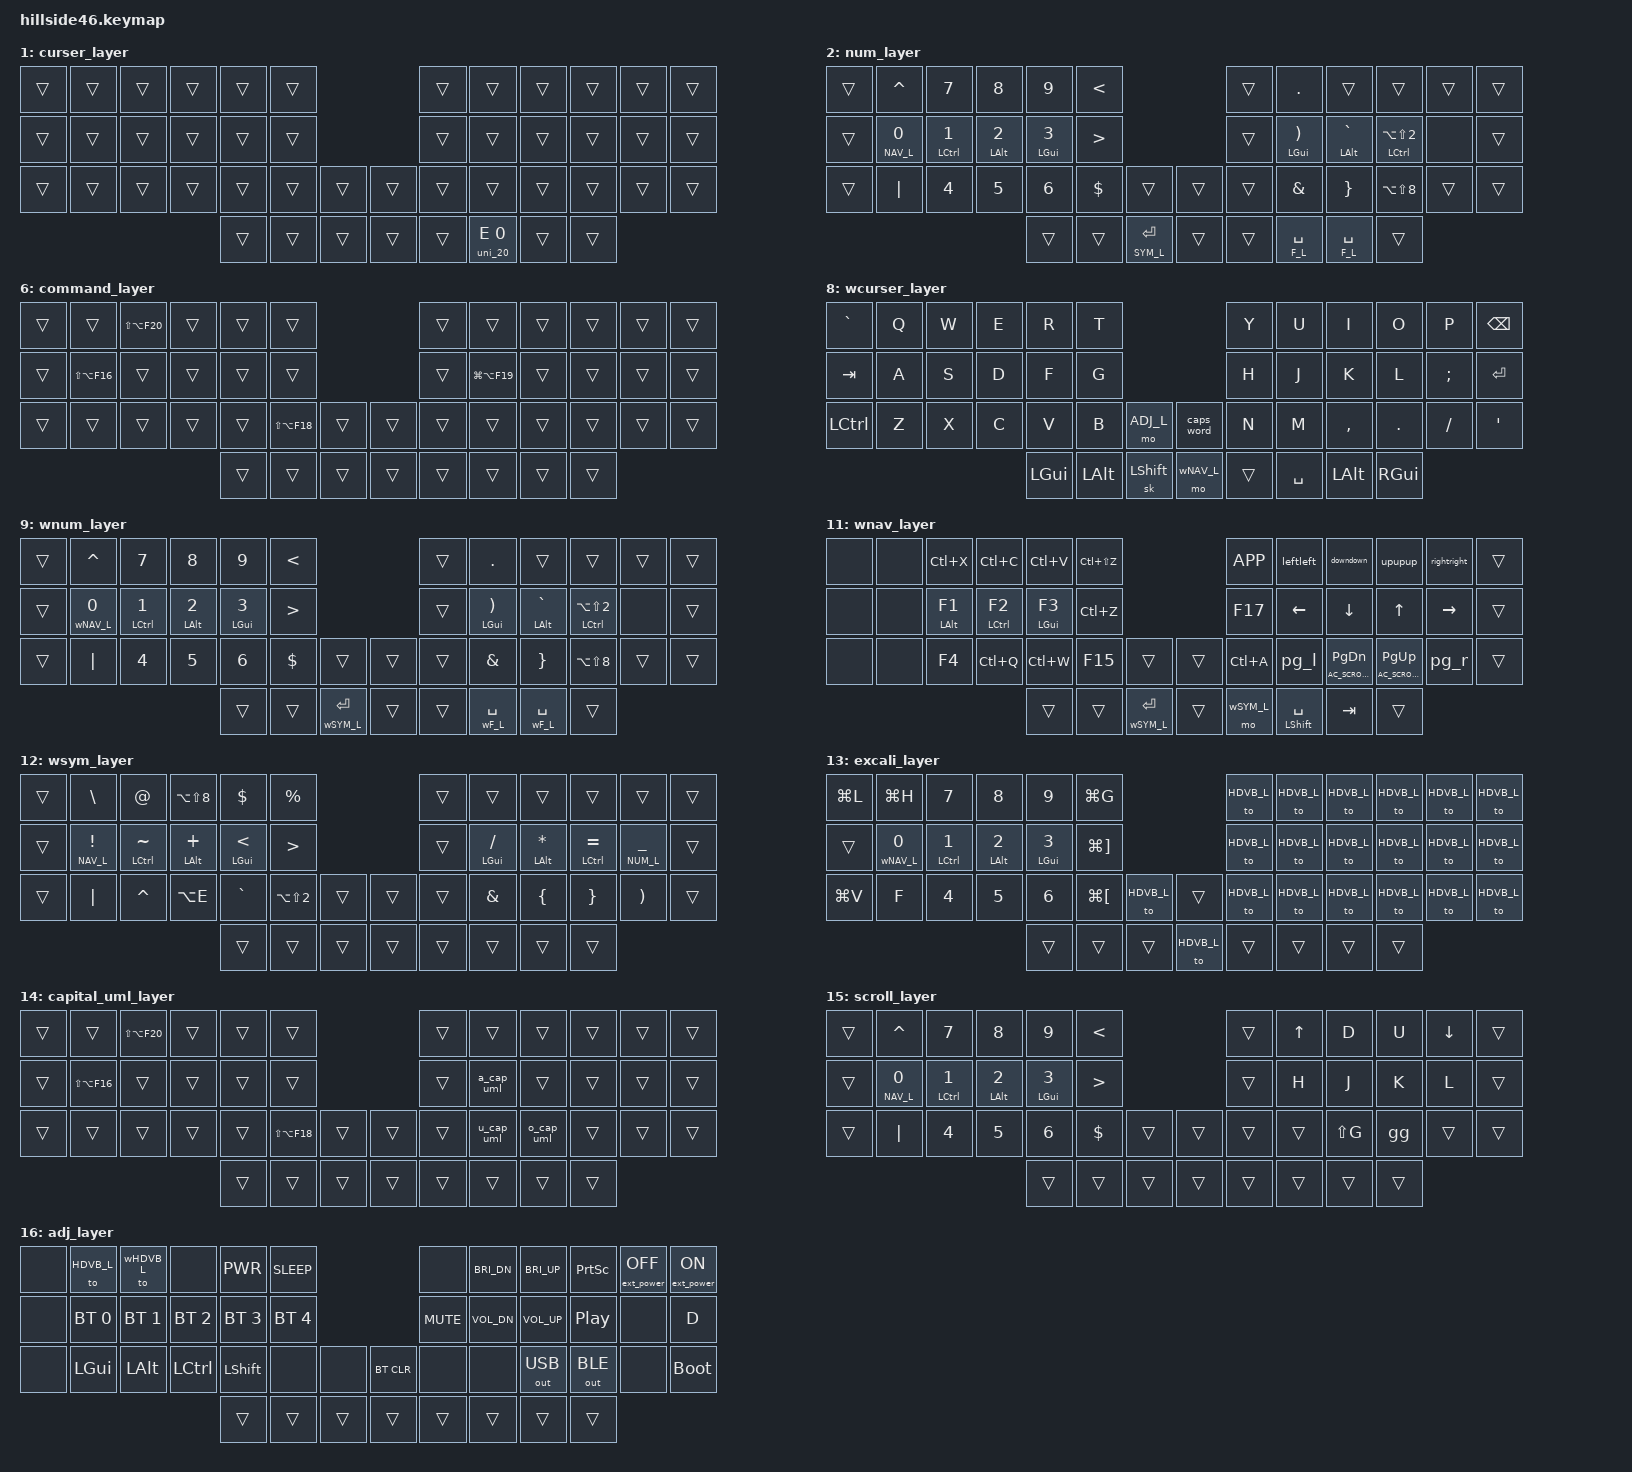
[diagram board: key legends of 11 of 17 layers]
/*
 * Copyright (c) 2021-2022 The ZMK Contributors
 *
 * SPDX-License-Identifier: MIT
 */

#include <behaviors.dtsi>
#include <dt-bindings/zmk/bt.h>
#include <dt-bindings/zmk/ext_power.h>
#include <dt-bindings/zmk/keys.h>
#include <dt-bindings/zmk/outputs.h>
#include "german-keymap.h"

// Mac
#define HDVB_L   0
#define CURSER_L 1
#define NUM_L    2
#define F_L      3
#define NAV_L    4
#define SYM_L    5
#define COM_L    6

// Win
#define wHDVB_L   7
#define wCURSER_L 8
#define wNUM_L    9
#define wF_L      10
#define wNAV_L    11
#define wSYM_L    12

#define EXCALI   13
#define UML_L    14
#define SCROLL_L 15
#define ADJ_L    16


#define LEFT_ROW_0       0  1  2  3  4  5  
#define LEFT_ROW_1      12 13 14 15 16 17
#define LEFT_ROW_2      24 25 26 27 28 29
#define LEFT_ROW_3               38 39 40 41 30
#define RIGT_ROW_0                         6  7  8  9 10 11
#define RIGT_ROW_1                        18 19 20 21 22 23
#define RIGT_ROW_2                        32 33 34 35 36 37
#define RIGT_ROW_3                  31 42 43 44 45
#define LEFT_ROWS_012   LEFT_ROW_0 LEFT_ROW_1 LEFT_ROW_2
#define RIGT_ROWS_012   RIGT_ROW_0 RIGT_ROW_1 RIGT_ROW_2

&sl {
    release-after-ms = <500>;
    quick-release;
};

// ▄▄▄▄▄▄▄▄▄▄▄▄▄▄▄▄▄▄▄▄▄▄▄▄▄▄▄▄▄▄▄▄▄▄▄▄▄▄▄▄▄▄▄▄▄▄▄▄▄▄▄▄▄▄▄▄▄▄▄▄▄▄▄▄▄▄▄▄▄▄▄▄▄▄▄▄▄▄▄▄▄▄▄▄▄▄▄▄▄▄▄▄▄▄▄▄▄▄▄▄▄▄▄▄▄▄▄▄▄▄▄▄▄▄▄▄▄▄▄▄▄▄▄▄▄▄▄▄▄▄▄▄▄▄▄▄▄▄▄▄▄▄
// ▄▄▄▄▄▄▄▄▄▄▄▄▄▄▄▄▄▄▄▄▄▄▄▄▄▄▄▄▄▄▄▄▄▄▄▄▄▄▄▄▄▄▄▄▄▄▄▄▄▄▄▄▄▄▄▄▄▄▄▄▄▄▄▄▄▄▄▄▄▄▄▄▄▄▄▄▄▄▄▄▄▄▄▄▄▄▄▄▄▄▄▄▄▄▄▄▄▄▄▄▄▄▄▄▄▄▄▄▄▄▄▄▄▄▄▄▄▄▄▄▄▄▄▄▄▄▄▄▄▄▄▄▄▄▄▄▄▄▄▄▄▄
/ {

 // MACRO ▄▄▄▄▄▄▄▄▄▄▄▄▄▄▄▄▄▄▄▄▄▄▄▄▄▄▄▄▄▄▄▄▄▄▄▄▄▄▄▄▄▄▄▄▄▄▄▄▄▄▄▄▄▄▄▄▄▄▄▄▄▄▄▄▄▄▄▄▄▄▄▄▄▄▄▄▄▄▄▄▄▄▄▄▄▄▄▄▄▄▄▄▄▄▄▄▄▄▄▄▄▄▄▄▄▄▄▄▄▄▄▄▄▄▄▄▄▄▄▄▄▄▄▄▄▄▄▄▄▄▄▄▄▄▄▄▄▄▄▄▄▄
    macros {
        
	    spc_sh: space_shift_macro {
	        compatible = "zmk,behavior-macro";
        	label = "MACRO1";
	        #binding-cells = <0>;
            bindings = <&macro_tap &kp SPACE &skq RSHIFT>;
	    };
        sp_sh: sp_sh {
	        compatible = "zmk,behavior-macro";
        	label = "SPACE_SHIFT_HOLD";
	        #binding-cells = <0>;
            bindings
                = <&macro_tap &kp SPACE>
                , <&macro_press &sh_s_ht RSHIFT RSHIFT>
                , <&macro_pause_for_release>
                , <&macro_release &sh_s_ht RSHIFT RSHIFT>;
	    };

        spc_l: space_layer_macro {
	        compatible = "zmk,behavior-macro";
        	label = "SPACE_LAYER";
	        #binding-cells = <0>;
        	bindings = <&macro_tap &kp SPACE &sl CURSER_L>;
	    };

	    comm_l: comm_l {
	        compatible = "zmk,behavior-macro";
        	label = "COMMAND_Layer";
	        #binding-cells = <0>;
        	wait-ms = <0>;
            tap-ms = <0>;
            bindings 
                = <&macro_press &kp LGUI &mo COM_L>
                , <&macro_pause_for_release>
                , <&macro_release &kp LGUI &mo COM_L>;
	    };

        scroll: scroll {
            compatible = "zmk,behavior-macro";
        	label = "SCROLL";
            #binding-cells = <0>;
        	wait-ms = <0>;
            tap-ms = <0>;
            bindings 
                = <&macro_tap &kp LA(LS(LC(F17)))>
                // , <&macro_wait_time 200>
                , <&macro_press &mo SCROLL_L>
                //, <&macro_tap &kp &kp LG(LC(LS(LA(R))))>
                , <&macro_pause_for_release>
                , <&macro_release &mo SCROLL_L>
                , <&macro_tap &kp LA(LS(LC(F18)))>;
        };

        // fixing grave and backslash
        b_slsh: b_slsh {
            compatible = "zmk,behavior-macro";
            label = "BSLASH_BSLASH";
            #binding-cells = <0>;
            bindings = <&macro_tap &kp F16 &kp BSLH>;
	    };
        
     // Arrows ▄▄▄▄▄▄▄▄▄▄▄▄▄▄▄▄▄▄▄▄▄▄▄▄▄▄▄▄▄▄▄▄▄▄▄▄▄▄▄▄▄▄▄▄▄▄▄▄▄▄▄▄▄▄▄▄▄▄▄▄▄▄▄▄▄▄▄▄▄▄▄▄▄▄▄▄▄▄▄▄▄▄▄▄▄▄▄▄▄▄▄▄▄▄▄▄▄▄▄▄▄▄▄▄▄▄▄▄▄▄▄▄▄▄▄▄▄▄▄▄▄▄▄▄▄▄▄▄▄▄▄▄▄▄▄▄▄▄▄▄▄▄
            upupup: upupup {
             label = "UPUPUP";
             compatible = "zmk,behavior-macro";
             #binding-cells = <0>;
             wait-ms = <0>;
             tap-ms = <0>;
             bindings
                 = <&macro_tap &kp UP &kp UP &kp UP &kp UP &kp UP>
                 ;
         };
         downdown: downdown {
             label = "DOWNDOWN";
             compatible = "zmk,behavior-macro";
             #binding-cells = <0>;
             wait-ms = <0>;
             tap-ms = <0>;
             bindings
                 = <&macro_tap &kp DOWN &kp DOWN &kp DOWN &kp DOWN &kp DOWN>
                 ;
         };
         rightright: rightright {
             label = "RIGHTRIGHT";
             compatible = "zmk,behavior-macro";
             #binding-cells = <0>;
             wait-ms = <0>;
             tap-ms = <0>;
             bindings
                 = <&macro_tap &kp RIGHT &kp RIGHT &kp RIGHT &kp RIGHT &kp RIGHT>
                 ;
         };
         leftleft: leftleft {
             label = "LEFTLEFT";
             compatible = "zmk,behavior-macro";
             #binding-cells = <0>;
             wait-ms = <0>;
             tap-ms = <0>;
             bindings
                 = <&macro_tap &kp LEFT &kp LEFT &kp LEFT &kp LEFT &kp LEFT>
                 ;
         };
     // Enclose ▄▄▄▄▄▄▄▄▄▄▄▄▄▄▄▄▄▄▄▄▄▄▄▄▄▄▄▄▄▄▄▄▄▄▄▄▄▄▄▄▄▄▄▄▄▄▄▄▄▄▄▄▄▄▄▄▄▄▄▄▄▄▄▄▄▄▄▄▄▄▄▄▄▄▄▄▄▄▄▄▄▄▄▄▄▄▄▄▄▄▄▄▄▄▄▄▄▄▄▄▄▄▄▄▄▄▄▄▄▄▄▄▄▄▄▄▄▄▄▄▄▄▄▄▄▄▄▄▄▄▄▄▄▄▄▄▄▄▄▄▄▄
         kp_qu: kpqu {
             label = "Key_QU";
             compatible = "zmk,behavior-macro";
             #binding-cells = <0>;
             wait-ms = <0>;
             tap-ms = <0>;
             bindings = <&macro_tap &kp Q>
                 , <&macro_release &kp LSHFT>
                 , <&macro_release &kp RSHFT>
                 , <&macro_tap &kp U>
                 ;
         };
         SQT_close: SQT_close {
             label = "SQT_closer";
             compatible = "zmk,behavior-macro";
             #binding-cells = <0>;
             wait-ms = <0>;
             tap-ms = <0>;
             bindings = <&macro_tap &kp LG(X) &kp SQT &kp SQT &kp LEFT &kp LG(V)>
                 ;
         };
         PAR_close: PAR_close {
             label = "PAR_closer";
             compatible = "zmk,behavior-macro";
             #binding-cells = <0>;
             wait-ms = <0>;
             tap-ms = <0>;
             bindings = <&macro_tap &kp LG(X) &kp LPAR &kp RPAR &kp LEFT &kp LG(V)>
                 ;
         };
         DQT_close: DQT_close {
             label = "DQT_closer";
             compatible = "zmk,behavior-macro";
             #binding-cells = <0>;
             wait-ms = <0>;
             tap-ms = <0>;
             bindings = <&macro_tap &kp LG(X) &kp DQT &kp DQT &kp LEFT &kp LG(V)>
                 ;
         };
     // Signs ▄▄▄▄▄▄▄▄▄▄▄▄▄▄▄▄▄▄▄▄▄▄▄▄▄▄▄▄▄▄▄▄▄▄▄▄▄▄▄▄▄▄▄▄▄▄▄▄▄▄▄▄▄▄▄▄▄▄▄▄▄▄▄▄▄▄▄▄▄▄▄▄▄▄▄▄▄▄▄▄▄▄▄▄▄▄▄▄▄▄▄▄▄▄▄▄▄▄▄▄▄▄▄▄▄▄▄▄▄▄▄▄▄▄▄▄▄▄▄▄▄▄▄▄▄▄▄▄▄▄▄▄▄▄▄▄▄▄▄▄▄▄
         EURO: euro {
             label = "EURO";
             compatible = "zmk,behavior-macro";
             #binding-cells = <0>;
             wait-ms = <0>;
             tap-ms = <0>;
             bindings = <&macro_press &kp LALT>
                 , <&macro_tap &kp N0 &kp N1 &kp N2 &kp N8>
                 , <&macro_release &kp LALT>
                 ;
         };
         accent_a_macro: accent_a_macro {
            compatible = "zmk,behavior-macro";
            label = "new_macro";
            #binding-cells = <0>;
            bindings =
                <&macro_press>,
                <&kp RALT &kp RSHFT>,
                <&macro_tap>,
                <&kp KP_N0 &kp KP_N2 &kp KP_N2 &kp KP_N5>,
                <&macro_release>,
                <&kp RSHFT &kp RALT>;
        };
        /* For Unicode codes in the U+00XX range */
        uni_00: uni_00 {
            compatible = "zmk,behavior-macro-two-param";
            label = "UNICODE_00";
            wait-ms = <0>;
            tap-ms = <0>;
            #binding-cells = <2>;
            bindings
                = <&macro_press   &kp LALT>
                , <&macro_tap     &kp KP_N0 &kp KP_N0>
                , <&macro_param_1to1>
                , <&macro_tap &kp MACRO_PLACEHOLDER>
                , <&macro_param_2to1>
                , <&macro_tap &kp MACRO_PLACEHOLDER>
                , <&macro_release &kp LALT>
                ;
        };

        /* For Unicode codes in the U+01XX range (e.g. ħ U+0127) */
        uni_01: uni_01 {
            compatible = "zmk,behavior-macro-two-param";
            label = "UNICODE_01";
            wait-ms = <0>;
            tap-ms = <0>;
            #binding-cells = <2>;
            bindings =
                <&macro_press   &kp LALT>,
                <&macro_tap     &kp KP_N0 &kp KP_N1>,
                <&macro_param_1to1>,
                <&macro_tap     &kp MACRO_PLACEHOLDER>,
                <&macro_param_2to1>,
                <&macro_tap     &kp MACRO_PLACEHOLDER>,
                <&macro_release &kp LALT>
                ;
        };

        /* For Unicode codes in the U+03XX range (Greek letters, etc.) */
        uni_03: uni_03 {
            compatible = "zmk,behavior-macro-two-param";
            label = "UNICODE_03";
            wait-ms = <0>;
            tap-ms = <0>;
            #binding-cells = <2>;
            bindings =
                <&macro_press   &kp LALT>,
                <&macro_tap     &kp KP_N0 &kp KP_N3>,
                <&macro_param_1to1>,
                <&macro_tap     &kp MACRO_PLACEHOLDER>,
                <&macro_param_2to1>,
                <&macro_tap     &kp MACRO_PLACEHOLDER>,
                <&macro_release &kp LALT>
                ;
        };

        /* For Unicode codes in the U+20XX range (e.g. em-dash) */
        uni_20: uni_20 {
            compatible = "zmk,behavior-macro-two-param";
            label = "UNICODE_20";
            wait-ms = <0>;
            tap-ms = <0>;
            #binding-cells = <2>;
            bindings =
                <&macro_press   &kp LALT>,
                <&macro_tap     &kp KP_N2 &kp KP_N0>,
                <&macro_param_1to1>,
                <&macro_tap     &kp MACRO_PLACEHOLDER>,
                <&macro_param_2to1>,
                <&macro_tap     &kp MACRO_PLACEHOLDER>,
                <&macro_release &kp LALT>
                ;
        };

        /* For Unicode codes in the U+22XX range (many math symbols) */
        uni_22: uni_22 {
            compatible = "zmk,behavior-macro-two-param";
            label = "UNICODE_22";
            wait-ms = <0>;
            tap-ms = <0>;
            #binding-cells = <2>;
            bindings =
                <&macro_press   &kp LALT>,
                <&macro_tap     &kp KP_N2 &kp KP_N2>,
                <&macro_param_1to1>,
                <&macro_tap     &kp MACRO_PLACEHOLDER>,
                <&macro_param_2to1>,
                <&macro_tap     &kp MACRO_PLACEHOLDER>,
                <&macro_release &kp LALT>
                ;
        };
        /* For Unicode codes in the U+25XX range (arrows, etc.) */
        uni_25: uni_25 {
            compatible = "zmk,behavior-macro-two-param";
            label = "UNICODE_25";
            wait-ms = <0>;
            tap-ms = <0>;
            #binding-cells = <2>;
            bindings =
                <&macro_press   &kp LALT>,
                <&macro_tap     &kp KP_N2 &kp KP_N5>,
                <&macro_param_1to1>,
                <&macro_tap     &kp MACRO_PLACEHOLDER>,
                <&macro_param_2to1>,
                <&macro_tap     &kp MACRO_PLACEHOLDER>,
                <&macro_release &kp LALT>
                ;
        };
        /* For Unicode codes in the U+27XX range (many math symbols) */
        uni_27: uni_27 {
            compatible = "zmk,behavior-macro-two-param";
            label = "UNICODE_22";
            wait-ms = <0>;
            tap-ms = <0>;
            #binding-cells = <2>;
            bindings =
                <&macro_press   &kp LALT>,
                <&macro_tap     &kp KP_N2 &kp KP_N7>,
                <&macro_param_1to1>,
                <&macro_tap     &kp MACRO_PLACEHOLDER>,
                <&macro_param_2to1>,
                <&macro_tap     &kp MACRO_PLACEHOLDER>,
                <&macro_release &kp LALT>
                ;
        };
        a_uml: a_uml {
            compatible = "zmk,behavior-macro";
            label = "A_UML";
            #binding-cells = <0>;
            bindings =
                <&macro_press>,
                <&kp LALT &kp U>,
                <&macro_release>,
                <&kp U &kp LALT>,
                <&macro_tap>,
                <&kp A>;
        };
        o_uml: o_uml {
            compatible = "zmk,behavior-macro";
            label = "O_UML";
            #binding-cells = <0>;
            bindings =
                <&macro_press>,
                <&kp LALT &kp U>,
                <&macro_release>,
                <&kp U &kp LALT>,
                <&macro_tap>,
                <&kp O>;
        };
        u_uml: u_uml {
            compatible = "zmk,behavior-macro";
            label = "U_UML";
            #binding-cells = <0>;
            bindings =
                <&macro_press>,
                <&kp LALT &kp U>,
                <&macro_release>,
                <&kp U &kp LALT>,
                <&macro_tap>,
                <&kp U>;
        };
        a_cap_uml: a_cap_uml {
            compatible = "zmk,behavior-macro";
            label = "A_CAP_UML";
            #binding-cells = <0>;
            bindings =
                <&macro_press>,
                <&kp LALT &kp U>,
                <&macro_release>,
                <&kp U &kp LALT>,
                <&macro_press>,
                <&kp LSHFT>,
                <&macro_tap>,
                <&kp A>,
                <&macro_release>,
                <&kp LSHIFT>;
        };
        o_cap_uml: o_cap_uml {
            compatible = "zmk,behavior-macro";
            label = "O_CAP_UML";
            #binding-cells = <0>;
            bindings =
                <&macro_press>,
                <&kp LALT &kp U>,
                <&macro_release>,
                <&kp U &kp LALT>,
                <&macro_press>,
                <&kp LSHFT>,
                <&macro_tap>,
                <&kp O>,
                <&macro_release>,
                <&kp LSHIFT>;
        };
        u_cap_uml: u_cap_uml {
            compatible = "zmk,behavior-macro";
            label = "U_CAP_UML";
            #binding-cells = <0>;
            bindings =
                <&macro_press>,
                <&kp LALT &kp U>,
                <&macro_release>,
                <&kp U &kp LALT>,
                <&macro_press>,
                <&kp LSHFT>,
                <&macro_tap>,
                <&kp U>,
                <&macro_release>,
                <&kp LSHIFT>;
        };
        pg_r_com: pg_r_com {
            compatible = "zmk,behavior-macro";
            label = "PG_R_COM";
            #binding-cells = <0>;
            bindings =
                <&macro_press>,
                <&kp LCTRL>,
                <&macro_tap>,
                <&kp TAB>,
                <&macro_release>,
                <&kp LCTRL>;
        };
        pg_l_com: pg_l_com {
            compatible = "zmk,behavior-macro";
            label = "PG_L_COM";
            #binding-cells = <0>;
            bindings =
                <&macro_press>,
                <&kp LCTRL &kp LSHFT>,
                <&macro_tap>,
                <&kp TAB>,
                <&macro_release>,
                <&kp LCTRL &kp LSHFT>;
        };
     // Other ▄▄▄▄▄▄▄▄▄▄▄▄▄▄▄▄▄▄▄▄▄▄▄▄▄▄▄▄▄▄▄▄▄▄▄▄▄▄▄▄▄▄▄▄▄▄▄▄▄▄▄▄▄▄▄▄▄▄▄▄▄▄▄▄▄▄▄▄▄▄▄▄▄▄▄▄▄▄▄▄▄▄▄▄▄▄▄▄▄▄▄▄▄▄▄▄▄▄▄▄▄▄▄▄▄▄▄▄▄▄▄▄▄▄▄▄▄▄▄▄▄▄▄▄▄▄▄▄▄▄▄▄▄▄▄▄▄▄▄▄▄▄
         schnell_sch: schnell {
             label = "Schau_mal";
             compatible = "zmk,behavior-macro";
             #binding-cells = <0>;
             wait-ms = <0>;
             tap-ms = <0>;
             bindings = <&macro_tap &kp LG(X) &kp SQT &kp SQT &kp LEFT &kp LG(V)>
                 ;
         };

         gg: gg {
             label = "gg";
             compatible = "zmk,behavior-macro";
             #binding-cells = <0>;
             wait-ms = <0>;
             tap-ms = <0>;
             bindings = <&macro_tap &kp G &kp G>
                 ;
         };

         scroll_toggle: scroll_toggle {
            label = "scroll_toggle";
            compatible = "zmk,behavior-macro";
            #binding-cells = <0>;
            wait-ms = <0>;
            tap-ms = <0>;
            bindings = <&macro_tap &kp LG(LS(F19)) &tog SCROLL_L>
                 ;
         };
    };

    behaviors {

     // Home row mods ▄▄▄▄▄▄▄▄▄▄▄▄▄▄▄▄▄▄▄▄▄▄▄▄▄▄▄▄▄▄▄▄▄▄▄▄▄▄▄▄▄▄▄▄▄▄▄▄▄▄▄▄▄▄▄▄▄▄▄▄▄▄▄▄▄▄▄▄▄▄▄▄▄▄▄▄▄▄▄▄▄▄▄▄▄▄▄▄▄▄▄▄▄▄▄▄▄▄▄▄▄▄▄▄▄▄▄▄▄▄▄▄▄▄▄▄▄▄▄▄▄▄▄▄▄▄▄▄▄▄▄▄▄▄▄▄▄▄▄▄▄▄
      
        h_h: hold_tap_hold_prefered {
            compatible = "zmk,behavior-hold-tap";
            label = "HT_HP";
            #binding-cells = <2>;
            tapping-term-ms = <170>;
            quick_tap_ms = <0>;
            flavor = "hold-preferred";
            bindings = <&kp>, <&kp>;
        };
        h_b: ht_bl {
            compatible = "zmk,behavior-hold-tap";
            label = "HT_BL";
            #binding-cells = <2>;
            tapping-term-ms = <130>;
            quick_tap_ms = <0>;
            flavor = "balanced";
            bindings = <&kp>, <&kp>;
        };
        h_t: ht_tp {
            compatible = "zmk,behavior-hold-tap";
            label = "HT_TP";
            #binding-cells = <2>;
            tapping-term-ms = <100>;
            quick_tap_ms = <0>;
            flavor = "tap-preferred";
            bindings = <&kp>, <&kp>;
        };
        hm: homerow_mods {
            compatible = "zmk,behavior-hold-tap";
            label = "HOMEROW_MODS";
            #binding-cells = <2>;
            tapping-term-ms = <170>;
            quick_tap_ms = <0>;
            flavor = "tap-preferred";
            bindings = <&kp>, <&kp>;
        };
        hm_f: homerow_mods_fast {
            compatible = "zmk,behavior-hold-tap";
            label = "HOMEROW_MODS_FAST";
            #binding-cells = <2>;
            tapping-term-ms = <170>;
            quick_tap_ms = <0>;
            flavor = "hold-preferred";
            bindings = <&kp>, <&kp>;
        };

        hm_l: layer-homerow_mods {
            compatible = "zmk,behavior-hold-tap";
            label = "HOMEROW_MODS_L";
            #binding-cells = <2>;
            tapping-term-ms = <170>;
            quick_tap_ms = <0>;
            flavor = "tap-preferred";
            bindings = <&mo>, <&kp>;
        };
        gui_l: gui_l {
            compatible = "zmk,behavior-hold-tap";
            label = "GUI_LAYER";
            #binding-cells = <2>;
            tapping-term-ms = <170>;
            quick_tap_ms = <0>;
            flavor = "tap-preferred";
            bindings = <&comm_l>, <&kp>;
        };
     // special Linger ▄▄▄▄▄▄▄▄▄▄▄▄▄▄▄▄▄▄▄▄▄▄▄▄▄▄▄▄▄▄▄▄▄▄▄▄▄▄▄▄▄▄▄▄▄▄▄▄▄▄▄▄▄▄▄▄▄▄▄▄▄▄▄▄▄▄▄▄▄▄▄▄▄▄▄▄▄▄▄▄▄▄▄▄▄▄▄▄▄▄▄▄▄▄▄▄▄▄▄▄▄▄▄▄▄▄▄▄▄▄▄▄▄▄▄▄▄▄▄▄▄▄▄▄▄▄▄▄▄▄▄▄▄▄▄▄▄▄▄▄▄▄
        lk_qu: lk_qu {
            compatible = "zmk,behavior-hold-tap";
            label = "lk_qu";
            #binding-cells = <2>;
            tapping-term-ms = <170>;
            flavor = "tap-preferred";
            bindings = <&kp>, <&kp_qu>;
        };
        
     // Encloser ▄▄▄▄▄▄▄▄▄▄▄▄▄▄▄▄▄▄▄▄▄▄▄▄▄▄▄▄▄▄▄▄▄▄▄▄▄▄▄▄▄▄▄▄▄▄▄▄▄▄▄▄▄▄▄▄▄▄▄▄▄▄▄▄▄▄▄▄▄▄▄▄▄▄▄▄▄▄▄▄▄▄▄▄▄▄▄▄▄▄▄▄▄▄▄▄▄▄▄▄▄▄▄▄▄▄▄▄▄▄▄▄▄▄▄▄▄▄▄▄▄▄▄▄▄▄▄▄▄▄▄▄▄▄▄▄▄▄▄▄▄▄
        SQT_cl: SQT_cl {
            compatible = "zmk,behavior-hold-tap";
            label = "SQT_clr";
            #binding-cells = <2>;
            tapping-term-ms = <170>;
            flavor = "tap-preferred";
            bindings = <&SQT_close>, <&kp>;
        };
        PAR_cl: PAR_cl {
            compatible = "zmk,behavior-hold-tap";
            label = "PAR_clr";
            #binding-cells = <2>;
            tapping-term-ms = <200>;
            flavor = "tap-preferred";
            bindings = <&PAR_close>, <&kp>;
        };
        DQT_cl: DQT_cl {
            compatible = "zmk,behavior-hold-tap";
            label = "DQT_clr";
            #binding-cells = <2>;
            tapping-term-ms = <200>;
            flavor = "tap-preferred";
            bindings = <&DQT_close>, <&kp>;
        };

     // MOD MORPH ▄▄▄▄▄▄▄▄▄▄▄▄▄▄▄▄▄▄▄▄▄▄▄▄▄▄▄▄▄▄▄▄▄▄▄▄▄▄▄▄▄▄▄▄▄▄▄▄▄▄▄▄▄▄▄▄▄▄▄▄▄▄▄▄▄▄▄▄▄▄▄▄▄▄▄▄▄▄▄▄▄▄▄▄▄▄▄▄▄▄▄▄▄▄▄▄▄▄▄▄▄▄▄▄▄▄▄▄▄▄▄▄▄▄▄▄▄▄▄▄▄▄▄▄▄▄▄▄▄▄▄▄▄▄▄▄▄▄▄▄▄▄

        

        dot_brc: dot_brc {
            compatible = "zmk,behavior-mod-morph";
            #binding-cells = <0>;
            bindings = <&kp DOT>, <&kp LBRC>;
            mods = <(MOD_LSFT|MOD_RSFT)>;
        };
        slash_bslash: slash_bslash {
            compatible = "zmk,behavior-mod-morph";
            label = "SLASH_BSLASH";
            #binding-cells = <0>;
            bindings = <&kp SLASH>, <&b_slsh>;
            mods = <(MOD_LSFT|MOD_RSFT)>;
        };
        hash_per: hash_per {
            compatible = "zmk,behavior-mod-morph";
            label = "HASH_AT";
            #binding-cells = <0>;
            bindings = <&kp HASH>, <&kp PERCENT>;
            mods = <(MOD_LSFT|MOD_RSFT)>;
        };
        comma_par: comma_par {
            compatible = "zmk,behavior-mod-morph";
            label = "COMMA_par";
            #binding-cells = <0>;
            bindings = <&kp COMMA>, <&PAR_cl LPAR LPAR>;
            mods = <(MOD_LSFT|MOD_RSFT)>;
        };
        bkt_tilde: bkt_tilde {
            compatible = "zmk,behavior-mod-morph";
            label = "BKT_TILDE";
            #binding-cells = <0>;
            bindings = <&kp LBKT>, <&kp TILDE>;
            mods = <(MOD_LSFT|MOD_RSFT)>;
        };
        dqt_star: dqt_star {
            compatible = "zmk,behavior-mod-morph";
            label = "DQT_STAR";
            #binding-cells = <0>;
            bindings = <&kp DQT>, <&kp STAR>;
            mods = <(MOD_LSFT|MOD_RSFT)>;
        };
        dowdow_fold: dowdow_fold {
            compatible = "zmk,behavior-mod-morph";
            label = "DOWDOW_FOLD";
            #binding-cells = <0>;
            bindings = <&downdown >, <&kp LA(LG(RBKT))>;
            mods = <(MOD_LGUI|MOD_RGUI)>;
        };   
        upup_fold: upup_fold {
            compatible = "zmk,behavior-mod-morph";
            label = "DOWNDOWN_FOLD";
            #binding-cells = <0>;
            bindings = <&upupup >, <&kp LA(LG(LBKT))>;
            mods = <(MOD_LGUI|MOD_RGUI)>;
        };   
        sqt_at: SQTDQT {
            compatible = "zmk,behavior-mod-morph";
            label = "SQTDQT";
            #binding-cells = <0>;
            bindings = <&SQT_cl SQT SQT>, <&kp AT_SIGN>;
            mods = <(MOD_LSFT|MOD_RSFT)>;
        };
        pg_l: PG_LEFT {
            compatible = "zmk,behavior-mod-morph";
            label = "PG_LEFT";
            #binding-cells = <0>;
            bindings = <&kp HOME>, <&pg_l_com >;
            mods = <(MOD_LALT|MOD_RALT)>;
        };
        pg_r: PG_RIGHT {
            compatible = "zmk,behavior-mod-morph";
            label = "PG_RIGHT";
            #binding-cells = <0>;
            bindings = <&kp END>, <&pg_r_com >;
            mods = <(MOD_LALT|MOD_RALT)>;
        };

        bsp3: bsp3 {
                compatible = "zmk,behavior-mod-morph";
                label = "BSP3";
                #binding-cells = <0>;
                bindings = <&kp LA(BSPC)>, <&kp BSPC>;
                mods = <(MOD_LCTL|MOD_RCTL)>;
            };
            
        bsp4: bsp4 {
           compatible = "zmk,behavior-mod-morph";
            label = "BSP4";
            #binding-cells = <0>;
            bindings = <&bsp3>, <&kp TAB>;
            mods = <(MOD_LALT|MOD_RALT)>;
            keep-mods = <(MOD_LALT|MOD_RALT)>;
        };

        a_um: a_um  {
            compatible = "zmk,behavior-mod-morph";
            #binding-cells = <0>;
            bindings = <&a_uml>, <&a_cap_uml>;
            mods = <(MOD_LSFT|MOD_RSFT)>;
        };
        o_um: o_um {
            compatible = "zmk,behavior-mod-morph";
            #binding-cells = <0>;
            bindings = <&o_uml>, <&o_cap_uml>;
            mods = <(MOD_LSFT|MOD_RSFT)>;
        };
        u_um: u_um {
            compatible = "zmk,behavior-mod-morph";
            #binding-cells = <0>;
            bindings = <&u_uml>, <&u_cap_uml>;
            mods = <(MOD_LSFT|MOD_RSFT)>;
        };

        // Win
            bsp1: bsp1 {
                compatible = "zmk,behavior-mod-morph";
                label = "BSP1";
                #binding-cells = <0>;
                bindings = <&kp LC(BSPC)>, <&kp BSPC>;
                mods = <(MOD_LCTL|MOD_RCTL)>;
            };
            
            bsp2: bsp2 {
                compatible = "zmk,behavior-mod-morph";
                label = "BSP2";
                #binding-cells = <0>;
                bindings = <&bsp1>, <&kp TAB>;
                mods = <(MOD_LALT|MOD_RALT)>;
                keep-mods = <(MOD_LALT|MOD_RALT)>;
            };

        del1: del1 {
            compatible = "zmk,behavior-mod-morph";
            label = "DEL1";
            #binding-cells = <0>;
            bindings = <&kp DEL>, <&kp LC(DEL)>;
            mods = <(MOD_LSFT|MOD_RSFT)>;
        };
     // Sticky keys ▄▄▄▄▄▄▄▄▄▄▄▄▄▄▄▄▄▄▄▄▄▄▄▄▄▄▄▄▄▄▄▄▄▄▄▄▄▄▄▄▄▄▄▄▄▄▄▄▄▄▄▄▄▄▄▄▄▄▄▄▄▄▄▄▄▄▄▄▄▄▄▄▄▄▄▄▄▄▄▄▄▄▄▄▄▄▄▄▄▄▄▄▄▄▄▄▄▄▄▄▄▄▄▄▄▄▄▄▄▄▄▄▄▄▄▄▄▄▄▄▄▄▄▄▄▄▄▄▄▄▄▄▄▄▄▄▄▄▄▄▄▄

        skq: sticky_key_quick_release {
            compatible = "zmk,behavior-sticky-key";
            label = "STICKY_KEY_QUICK_RELEASE";
            #binding-cells = <1>;
            bindings = <&kp>;
            release-after-ms = <1000>;
            quick-release;
        };

        sk_l: sticky_key_layer {
            compatible = "zmk,behavior-sticky-key";
            label = "STICKY_KEY_LAYER";
            #binding-cells = <1>;
            bindings = <&mo>;
            release-after-ms = <500>;
            quick-release;
        };
     // Shift No ▄▄▄▄▄▄▄▄▄▄▄▄▄▄▄▄▄▄▄▄▄▄▄▄▄▄▄▄▄▄▄▄▄▄▄▄▄▄▄▄▄▄▄▄▄▄▄▄▄▄▄▄▄▄▄▄▄▄▄▄▄▄▄▄▄▄▄▄▄▄▄▄▄▄▄▄▄▄▄▄▄▄▄▄▄▄▄▄▄▄▄▄▄▄▄▄▄▄▄▄▄▄▄▄▄▄▄▄▄▄▄▄▄▄▄▄▄▄▄▄▄▄▄▄▄▄▄▄▄▄▄▄▄▄▄▄▄▄▄▄▄▄
        
        sh_s: sh_s {
            compatible = "zmk,behavior-hold-tap";
            label = "SH_S";
            #binding-cells = <2>;
            tapping-term-ms = <150>;
            quick_tap_ms = <0>;
            flavor = "balanced";
            bindings = <&kp>, <&spc_l>;
        };
        sh_s_ht: sh_s_ht {
            compatible = "zmk,behavior-hold-tap";
            label = "SH_S_HT";
            #binding-cells = <2>;
            tapping-term-ms = <150>;
            quick_tap_ms = <0>;
            flavor = "hold-preferred";
            bindings = <&kp>, <&skq>;
        };
        rbk_tild_lbkt: rbk_tild_lbkt {
            compatible = "zmk,behavior-hold-tap";
            label = "LBKT_TILD_RBKT";
            #binding-cells = <2>;
            tapping-term-ms = <170>;
            quick_tap_ms = <0>;
            flavor = "tap-preferred";
            bindings = <&kp>, <&bkt_tilde>;
        };
    };


 // Combo ▄▄▄▄▄▄▄▄▄▄▄▄▄▄▄▄▄▄▄▄▄▄▄▄▄▄▄▄▄▄▄▄▄▄▄▄▄▄▄▄▄▄▄▄▄▄▄▄▄▄▄▄▄▄▄▄▄▄▄▄▄▄▄▄▄▄▄▄▄▄▄▄▄▄▄▄▄▄▄▄▄▄▄▄▄▄▄▄▄▄▄▄▄▄▄▄▄▄▄▄▄▄▄▄▄▄▄▄▄▄▄▄▄▄▄▄▄▄▄▄▄▄▄▄▄▄▄▄▄▄▄▄▄▄▄▄▄▄▄▄▄▄
    combos {
        compatible = "zmk,combos";
        
        combo_z {
            timeout-ms = <70>;
            key-positions = <1 2>;
            bindings = <&kp Z>;
            layers = <0 7>;
        };

        combo_esc {
            timeout-ms = <50>;
            key-positions = <14 15 16>;
            bindings = <&kp ESC>;
        };

        combo_excali {
            timeout-ms = <50>;
            key-positions = <13 14 15 16>;
            bindings = <&tog EXCALI>;
        };

        combo_qu {
            timeout-ms = <70>;
            key-positions = <2 4>;
            bindings = <&lk_qu Q U>;
            layers = <0 7>;
        };

        combo_COLON {
            timeout-ms = <50>;
            key-positions = <8 9>;
            bindings = <&kp COLON>;
        };

        combo_SEMI {
            timeout-ms = <50>;
            key-positions = <7 8>;
            bindings = <&kp SEMI>;
        };

        combo_ques {
            timeout-ms = <50>;
            key-positions = <9 10>;
            bindings = <&kp QMARK>;
        };

        combo_excl {
            timeout-ms = <50>;
            key-positions = <7 10>;
            bindings = <&kp EXCL>;
        };

        combo_brac {
            timeout-ms = <50>;
            key-positions = <18 19>;
            bindings = <&PAR_cl LPAR LPAR>;
        };

        to_scroll_layer {
            timeout-ms = <50>;
            key-positions = <7 9>;
            bindings = <&scroll_toggle>;
        };

    };

// ▄▄▄▄▄▄▄▄▄▄▄▄▄▄▄▄▄▄▄▄▄▄▄▄▄▄▄▄▄▄▄▄▄▄▄▄▄▄▄▄▄▄▄▄▄▄▄▄▄▄▄▄▄▄▄▄▄▄▄▄▄▄▄▄▄▄▄▄▄▄▄▄▄▄▄▄▄▄▄▄▄▄▄▄▄▄▄▄▄▄▄▄▄▄▄▄▄▄▄▄▄▄▄▄▄▄▄▄▄▄▄▄▄▄▄▄▄▄▄▄▄▄▄▄▄▄▄▄▄▄▄▄▄▄▄▄▄▄▄▄▄▄
};
// ▄▄▄▄▄▄▄▄▄▄▄▄▄▄▄▄▄▄▄▄▄▄▄▄▄▄▄▄▄▄▄▄▄▄▄▄▄▄▄▄▄▄▄▄▄▄▄▄▄▄▄▄▄▄▄▄▄▄▄▄▄▄▄▄▄▄▄▄▄▄▄▄▄▄▄▄▄▄▄▄▄▄▄▄▄▄▄▄▄▄▄▄▄▄▄▄▄▄▄▄▄▄▄▄▄▄▄▄▄▄▄▄▄▄▄▄▄▄▄▄▄▄▄▄▄▄▄▄▄▄▄▄▄▄▄▄▄▄▄▄▄▄
// ▄▄▄▄▄▄▄▄▄▄▄▄▄▄▄▄▄▄▄▄▄▄▄▄▄▄▄▄▄▄▄▄▄▄▄▄▄▄▄▄▄▄▄▄▄▄▄▄▄▄▄▄▄▄▄▄▄▄▄▄▄▄▄▄▄▄▄▄▄▄▄▄▄▄▄▄▄▄▄▄▄▄▄▄▄▄▄▄▄▄▄▄▄▄▄▄▄▄▄▄▄▄▄▄▄▄▄▄▄▄▄▄▄▄▄▄▄▄▄▄▄▄▄▄▄▄▄▄▄▄▄▄▄▄▄▄▄▄▄▄▄▄
/ {
        keymap {
                compatible = "zmk,keymap";

                default_layer {

                        bindings = <
&slash_bslash &kp  W        &kp  X        &kp  M        &kp  G        &kp  J                                                                         &hash_per      &dot_brc     &rbk_tild_lbkt RBKT LBKT   &dqt_star    &sqt_at          &hm LC(LS(F18)) LC(LS(F15))
&kp  TAB      &hm_l NAV_L C &hm LCTRL S   &hm LALT N    &gui_l A T    &hm LSHIFT K                                                                   &comma_par    &gui_l A A    &hm LALT  E   &hm LCTRL  I   &hm_l NUM_L H    &kp  ENTER
&kp EQUAL     &kp  P        &kp  F        &kp  L        &kp  D        &kp  V        &mo  ADJ_L                                         &sys_reset       &kp MINUS     &kp  U        &kp  O        &kp  Y         &kp  B           &tog EXCALI
                                       &kp DEL       &kp BSPC      &hm_l SYM_L R    &h_h LG(LC(LALT)) LS(LA(LG(LC(F19))))   &h_h LG(LC(LS(LALT))) LS(LA(LG(LC(F20))))  &sh_s LSHIFT  SPACE &sp_sh &kp C_PLAY_PAUSE
                        >;
			
                        sensor-bindings = <&inc_dec_kp C_VOL_UP C_VOL_DN &inc_dec_kp PG_UP PG_DN>;
                };
		
                curser_layer {

                        bindings = <
&trans        &trans             &trans            &trans            &trans                &trans                                                               &trans        &trans             &trans            &trans            &trans                &trans
&trans        &trans             &trans            &trans            &trans                &trans                                                               &trans        &trans             &trans            &trans            &trans                &trans
&trans        &trans             &trans            &trans            &trans                &trans           &trans                          &trans              &trans        &trans             &trans            &trans            &trans                &trans           
                                                                     &trans                &trans           &trans    &trans     &trans     &uni_20 E N0              &trans        &trans
                        >;
			
                        sensor-bindings = <&inc_dec_kp C_VOL_UP C_VOL_DN &inc_dec_kp PG_UP PG_DN>;
                };
		
                num_layer {

                        bindings = <
&trans        &kp  CARET     &kp  N7       &kp  N8       &kp  N9        &kp  LT                                                                         &trans        &kp DOT           &trans         &trans         &trans       &trans        
&trans        &hm_l NAV_L N0 &hm LCTRL N1  &hm LALT N2   &hm LGUI N3    &kp  GT                                                                         &trans        &hm LGUI RPAR    &hm LALT GRAVE  &hm LCTRL LA(LS(NUMBER_2))    &none        &trans        
&trans        &kp  PIPE     &kp  N4       &kp  N5       &kp  N6        &kp  DOLLAR  &trans                                             &trans          &trans        &kp  AMPS        &kp  RBRC        &kp LA(LS(NUMBER_8))      &trans       &trans        
                                                        &trans         &trans        &hm_l SYM_L RETURN    &trans            &trans     &hm_l F_L SPACE     &hm_l F_L SPACE  &trans
                        >;
			
                        sensor-bindings = <&inc_dec_kp C_VOL_UP C_VOL_DN &inc_dec_kp PG_UP PG_DN>;
                };
		
                l_layer {

                        bindings = <
&kp BACKSLASH &kp F12        &kp  F7       &kp  F8       &kp  F9       &kp  F13                                                                       &kp PERCENT   &kp LBRC               &kp TILDE                   &kp LA(LS(NUMBER_8))        &trans       &trans        
&kp LS(TAB)  &hm_l NAV_L F10 &hm LCTRL F1   &hm LALT F2  &hm LGUI F3   &kp  F14                                                                       &kp LPAR      &hm LGUI F20            &hm LALT LS(LA(LG(LC(F17))))  &hm LCTRL LS(LA(LG(LC(F14))))   &none        &trans        
&kp PLUS     &kp F11         &kp  F4       &kp  F5       &kp  F6       &kp  F15      &trans                                             &trans        &kp UNDER     &kp LS(LA(LG(LC(F12)))) &kp LS(LA(LG(LC(F16))))   &kp LS(LA(LG(LC(F13))))   &trans       &trans        
                                                          &trans         &trans        &hm_l SYM_L RETURN    &trans            &trans     &trans        &trans        &trans
                        >;
			
                        sensor-bindings = <&inc_dec_kp C_VOL_UP C_VOL_DN &inc_dec_kp PG_UP PG_DN>;
                };
		
                nav_layer {

                        bindings = <
&none     &none         &kp  LG(X)      &kp  LG(C)     &kp  LG(V)    &kp  LG(LS(Z))                                                                      &kp   K_APP   &leftleft    &dowdow_fold   &upup_fold    &rightright   &trans
&none     &none         &hm_f LCTRL F1  &hm_f LALT F2  &hm_f LGUI F3 &kp LG(Z)                                                                           &kp F17       &kp  LEFT    &kp   DOWN     &kp   UP      &kp  RIGHT    &trans
&none     &none         &kp  F4         &kp  LG(Q)     &kp  LG(W)    &kp  LG(LS(K))      &trans                                           &trans               &kp LG(A)     &pg_l     &hm C_AC_SCROLL_DOWN PG_DN &hm C_AC_SCROLL_UP PG_UP &pg_r      &trans
                                                       &trans        &trans        &hm_l SYM_L RETURN  &scroll           &kp LA(LS(LG(LC(SPACE))))  &hm LSHIFT SPACE     &kp TAB       &trans 
                        >;
			
                        sensor-bindings = <&inc_dec_kp PG_UP PG_DN &inc_dec_kp C_VOL_UP C_VOL_DN>;
                };

                sym_layer {

/* HD-Vibranium Uncommon Symbols Layer
 * -------------------------------------------------------------------------------------------------------------------------------------
 * |  ╱    |   ∧   |   ¬   |   ➡   |   ∴   |   ⊥   |-----------------------------------|   ∑   |   √   |   ≈   |   ²   |      |   π   |
 * | TAB   |   ç   |   ß   |   ¬   |   ⟷   |   κ   |-----------------------------------|   ∂   |   ä   |   ∈   |   ∩   |   ∞   | ENTER |
 * | ≠     |   ∝   |   ∀   |   λ   |   δ   |   ν   |  ADJ_L  |-------------------| sys   |   —   |   ö   |   ü   |   ¥   |   β   | none  |
 *                                         |  DEL  |  BSPC  | SYM_L | LG/LS(F19)      | LG/LS(F20)    |LSHIFT SPACE| SP  | C_PLAY_PAUSE |
 */


                        bindings = <
&kp LA(LS(F14))  &kp RA(LC(F15))  &kp LC(LS(F16))  &kp LG(LA(F17))  &kp LC(LG(F18))  &kp RA(LS(F19))                                                               &kp LA(LC(F20))  &kp LC(LS(F17))  &kp LA(LG(F19))  &kp LA(RA(SLASH))  &trans          &trans
&kp LA(F24)      &kp RA(LS(F13))  &kp LC(LS(F12))  &kp LG(LA(F11))  &kp LC(LS(F11))      &kp LA(RA(F10))                                                               &kp LC(LG(F9))   &a_um   &kp LA(LC(F7))   &kp LC(RA(F6))   &kp RA(LS(F5))  &kp ENTER
&kp LG(LC(F4))   &kp LA(RA(F3))   &kp LC(LS(F2))   &kp LG(LA(F1))   &kp RA(LS(F8))  &kp LC(LG(F15))  &mo ADJ_L                                     &sys_reset     &kp LA(LC(F16))  &u_um  &o_um &kp LG(LA(F18))   &kp LC(LG(F20))  &none
                                    &kp DEL        &kp BSPC       &hm_l SYM_L R   &h_h LG(LC(LALT)) LS(LA(LG(LC(F21))))          &h_h LG(LC(LS(LALT))) LS(LA(LG(LC(F22))))   &hm_l SCROLL_L  SPACE   &spc_sh   &kp C_PLAY_PAUSE
                        >;



			
                        sensor-bindings = <&inc_dec_kp PG_UP PG_DN &inc_dec_kp C_VOL_UP C_VOL_DN>;
                };

                command_layer {

                        bindings = <
&trans        &trans             &kp LS(LA(F20))   &trans            &trans                &trans                                                               &trans        &trans             &trans            &trans            &trans                &trans
&trans        &kp LS(LA(F16))    &trans            &trans            &trans                &trans                                                               &trans        &kp LG(LA(F19))    &trans            &trans            &trans                &trans
&trans        &trans             &trans            &trans            &trans                &kp LS(LA(F18))  &trans                          &trans              &trans        &trans             &trans            &trans            &trans                &trans
                                                   &trans            &trans                &trans       &trans                              &trans              &trans        &trans             &trans 
                        >;
			
                        sensor-bindings = <&inc_dec_kp PG_UP PG_DN &inc_dec_kp C_VOL_UP C_VOL_DN>;
                };


// Win ▄▄▄▄▄▄▄▄▄▄▄▄▄▄▄▄▄▄▄▄▄▄▄▄▄▄▄▄▄▄▄▄▄▄▄▄▄▄▄▄▄▄▄▄▄▄▄▄▄▄▄▄▄▄▄▄▄▄▄▄▄▄▄▄▄▄▄▄▄▄▄▄▄▄▄▄▄▄▄▄▄▄▄▄▄▄▄▄▄▄▄▄▄▄▄▄▄▄▄▄▄▄▄▄▄▄▄▄▄▄▄▄▄▄▄▄▄▄▄▄▄▄▄▄▄▄▄▄▄▄▄▄▄▄▄▄▄▄▄▄▄▄▄▄▄▄▄▄▄▄▄▄▄▄▄▄▄▄▄▄▄▄▄▄▄▄▄▄▄▄▄▄▄▄▄▄▄▄▄▄▄▄▄▄▄▄▄▄▄▄▄▄▄▄▄▄▄▄▄▄▄▄▄▄▄▄▄▄▄▄▄▄▄▄▄▄▄▄▄▄▄▄▄▄▄▄▄▄▄▄▄▄▄▄▄▄▄▄▄▄▄▄▄▄▄▄▄▄▄▄▄▄▄▄▄▄▄▄▄▄▄▄▄▄▄▄▄▄▄▄▄▄▄▄▄▄▄▄▄▄▄▄▄▄

                wdefault_layer {
/* HD-Vibranium
 * -------------------------------------------------------------------------------------------------------------------------------------
 * | `     |   '   |   ,   |   .   |   P   |   Y   |-----------------------------------|   F   |   G   |   C   |   R   |   L   | BKSPC |
 * | TAB   |   A   |   O   |   E   |   U   |   I   |-----------------------------------|   D   |   H   |   T   |   N   |   S   | ENTER |
 * | CTRL  |   ;   |   Q   |   J   |   K   |   X   |  ESC  |-------------------| CAPS  |   B   |   M   |   W   |   V   |   Z   |   /   |
 *                                 |  GUI  |  ALT  |SK SHFT|  Nav  |---|  Sym  | SPACE |  ALT  |  GUI  |
 */
                        bindings = <
&slash_bslash &kp  W        &kp  X        &kp  M        &kp  G        &kp  J                                                                         &kp  HASH  &kp  DOT   &hm RBKT LBKT &DQT_cl DQT DQT &sqt_at          &kp DEL
&kp  TAB      &hm_l wNAV_L C &hm LCTRL S   &hm LALT N    &gui_l A T    &kp  K                                                                         &comma_par    &gui_l A A    &hm LALT  E   &hm LCTRL  I   &hm_l wNUM_L H    &kp  ENTER
&kp EQUAL       &kp  P        &kp  F        &kp  L        &kp  D        &kp  V        &mo  ADJ_L                                         &none         &kp MINUS  &kp  U        &kp  O        &kp  Y     &kp  B           &none
                                                        &kp DEL         &kp BSPC         &hm_l wSYM_L R    &h_h LG(LC(LALT)) LS(LA(LG(LC(F19))))               &h_h LG(LC(LS(LALT))) LS(LA(LG(LC(F20))))  &h_b LSHIFT  SPACE  &spc_sh &kp C_PLAY_PAUSE
                        >;
			
                        sensor-bindings = <&inc_dec_kp C_VOL_UP C_VOL_DN &inc_dec_kp PG_UP PG_DN>;
                };
		
                wcurser_layer {
/* QWERTY
 * -------------------------------------------------------------------------------------------------------------------------------------
 * | `     |   Q   |   W   |   E   |   R   |   T   |-----------------------------------|   Y   |   U   |   I   |   O   |   P   | BKSPC |
 * | TAB   |   A   |   S   |   D   |   F   |   G   |-----------------------------------|   H   |   J   |   K   |   L   |   ;   | ENTER |
 * | CTRL  |   Z   |   X   |   C   |   V   |   B   |  ESC  |-------------------|  CAPS |   N   |   M   |   ,   |   .   |   /   |   '   |
 *                                 |  GUI  |  ALT  |SK SHFT|  Nav  |---|  Sym  | SPACE |  ALT  |  GUI  |
 */
                        bindings = <
&kp  GRAVE    &kp  Q        &kp  W        &kp  E        &kp  R        &kp  T                                                                         &kp  Y        &kp  U        &kp  I        &kp  O        &kp  P        &kp  BSPC
&kp  TAB      &kp  A        &kp  S        &kp  D        &kp  F        &kp  G                                                                         &kp  H        &kp  J        &kp  K        &kp  L        &kp  SEMI     &kp  ENTER  
&kp  LCTRL    &kp  Z        &kp  X        &kp  C        &kp  V        &kp  B        &mo  ADJ_L                                         &caps_word    &kp  N        &kp  M        &kp  COMMA    &kp  DOT      &kp  SLASH    &kp  SQT
                                                        &kp  LGUI     &kp  LALT     &sk  LSHIFT    &mo  wNAV_L            &trans        &kp  SPACE    &kp  LALT     &kp  RGUI
                        >;
			
                        sensor-bindings = <&inc_dec_kp C_VOL_UP C_VOL_DN &inc_dec_kp PG_UP PG_DN>;
                };
		
                wnum_layer {
/* NUM-Layer
 * -------------------------------------------------------------------------------------------------------------------------------------
 * | `     |   Q   |   W   |   F   |   P   |   B   |-----------------------------------|   #   |   .   |  [ ]  |   "   |   '   |       |
 * |       |   !   |   -   |   =   |   <   |   >   |-----------------------------------|   ,   |   Ä   |       |   ß   |       |  Ent  |
 * | Ctrl  |   |   |   ^   |   +   |   {   |   }   |       |-------------------|       |   -   |   Ü   |   ö   |       |       |       |
 *                                 |       |       |       |        |---|      |       |       |       |
 */
                        bindings = <
&trans        &kp  CARET     &kp  N7       &kp  N8       &kp  N9        &kp  LT                                                                         &trans        &kp DOT           &trans         &trans         &trans       &trans        
&trans        &hm_l wNAV_L N0 &hm LCTRL N1  &hm LALT N2   &hm LGUI N3    &kp  GT                                                                         &trans        &hm LGUI RPAR    &hm LALT GRAVE  &hm LCTRL LA(LS(NUMBER_2))    &none        &trans        
&trans        &kp  PIPE     &kp  N4       &kp  N5       &kp  N6        &kp  DOLLAR  &trans                                             &trans          &trans        &kp  AMPS        &kp  RBRC        &kp LA(LS(NUMBER_8))      &trans       &trans        
                                                        &trans         &trans        &hm_l wSYM_L RETURN    &trans            &trans     &hm_l wF_L SPACE     &hm_l wF_L SPACE  &trans
                        >;
			
                        sensor-bindings = <&inc_dec_kp C_VOL_UP C_VOL_DN &inc_dec_kp PG_UP PG_DN>;
                };
		
                wl_layer {
/* NUM-Layer
 * -------------------------------------------------------------------------------------------------------------------------------------
 * | `     |   Q   |   W   |   F   |   P   |   B   |-----------------------------------|   #   |   .   |  [ ]  |   "   |   '   |       |
 * |       |   !   |   -   |   =   |   <   |   >   |-----------------------------------|   ,   |   Ä   |       |   ß   |       |  Ent  |
 * | Ctrl  |   |   |   ^   |   +   |   {   |   }   |       |-------------------|       |   -   |   Ü   |   ö   |       |       |       |
 *                                 |       |       |       |        |---|      |       |       |       |
 */
                        bindings = <
&kp BACKSLASH &kp F12        &kp  F7       &kp  F8       &kp  F9       &kp  F13                                                                       &kp PERCENT   &kp LBRC               &kp TILDE                   &kp LA(LS(NUMBER_8))        &trans       &trans        
&kp LS(TAB)  &hm_l wNAV_L F10 &hm LCTRL F1   &hm LALT F2  &hm LGUI F3   &kp  F14                                                                       &kp LPAR      &hm LGUI F20            &hm LALT LS(LA(LG(LC(F17))))  &hm LCTRL LS(LA(LG(LC(F14))))   &none        &trans        
&kp PLUS     &kp F11         &kp  F4       &kp  F5       &kp  F6       &kp  F15      &trans                                             &trans        &kp UNDER     &kp LS(LA(LG(LC(F12)))) &kp LS(LA(LG(LC(F16))))   &kp LS(LA(LG(LC(F13))))   &trans       &trans        
                                                          &trans         &trans        &hm_l wSYM_L RETURN    &trans            &trans     &trans        &trans        &trans
                        >;

                        sensor-bindings = <&inc_dec_kp C_VOL_UP C_VOL_DN &inc_dec_kp PG_UP PG_DN>;
                };
		
                wnav_layer {
/* NAV   
 * -------------------------------------------------------------------------------------------------------------------------------------
 * | Copy  |   1   |   2   |   3   |   4   |   5   |-----------------------------------|   6   |   7   |   8   |   9   |   0   | BSPC  |
 * | Cut   |  GUI  |  Alt  | Ctrl  | Shift | Paste |-----------------------------------| PG UP |  Left |  Up   |  Down | Right | PG DN |
 * | Ctrl  |  F1   |  F2   |  F3   |  F4   |  F5   |  UnDo |-------------------| ReDo  |  F6   |  F7   |  F8   |  F9   |  F10  | Ctrl  |
 *                                 |       |       |       |       |---| ADJ_L |       |       |       |
 */
                        bindings = <
&none     &none         &kp  LC(X)      &kp  LC(C)     &kp  LC(V)    &kp  LC(LS(Z))                                                                      &kp   K_APP   &leftleft    &downdown      &upupup       &rightright   &trans
&none     &none         &hm_f LALT F1  &hm_f LCTRL F2  &hm_f LGUI F3 &kp LC(Z)                                                                           &kp F17       &kp  LEFT    &kp   DOWN     &kp   UP      &kp  RIGHT    &trans
&none     &none         &kp  F4         &kp  LC(Q)     &kp  LC(W)    &kp  F15      &trans                                           &trans               &kp LC(A)     &pg_l     &hm C_AC_SCROLL_DOWN PG_DN &hm C_AC_SCROLL_UP PG_UP &pg_r      &trans
                                                       &trans        &trans        &hm_l wSYM_L RETURN  &trans           &mo  wSYM_L  &hm LSHIFT SPACE     &kp TAB       &trans 
                        
                        >;
			
                        sensor-bindings = <&inc_dec_kp PG_UP PG_DN &inc_dec_kp C_VOL_UP C_VOL_DN>;
                };

                wsym_layer {
/* SYM
 * -------------------------------------------------------------------------------------------------------------------------------------
 * | INS   |   \   |   @   |   °   |   $   |   %   |-----------------------------------|   #   |   .   |  [ ]  |   "   |   '   |       |
 * |       |   !   |   ~   |   +   |   <   |   >   |-----------------------------------|   ,   |   /   |   *   |   =   |   _   |  Ent  |
 * | Ctrl  |   |   |   ^   |   ´   |   `   |       |       |-------------------|       |   -   |   &   |   {   |   }   |   )   |       |
 *                                 |       |       |       |        |---|      |       |       |       | 
 */
                        bindings = <
&trans   &kp  BSLH           &kp  AT_SIGN        &kp  LA(LS(NUMBER_8))       &kp  DOLLAR     &kp  PERCENT                                                                &trans        &trans             &trans            &trans            &trans                &trans
&trans   &hm_l NAV_L EXCL &hm LCTRL TILDE &hm LALT PLUS &hm LGUI LT &kp  GT                                                                  &trans        &hm LGUI SLASH &hm LALT STAR  &hm LCTRL EQUAL &hm_l NUM_L UNDER  &trans
&trans   &kp  PIPE        &kp CARET      &kp  LA(E)   &kp  GRAVE   &kp LA(LS(NUMBER_2)) &trans                                  &trans        &trans        &kp  AMPS          &kp  LBRC      &kp  RBRC      &kp  RPAR          &trans
                                                      &trans        &trans        &trans       &trans              &trans       &trans        &trans        &trans 
                        >;
			
                        sensor-bindings = <&inc_dec_kp PG_UP PG_DN &inc_dec_kp C_VOL_UP C_VOL_DN>;
                };

// ▄▄▄▄▄▄▄▄▄▄▄▄▄▄▄▄▄▄▄▄▄▄▄▄▄▄▄▄▄▄▄▄▄▄▄▄▄▄▄▄▄▄▄▄▄▄▄▄▄▄▄▄▄▄▄▄▄▄▄▄▄▄▄▄▄▄▄▄▄▄▄▄▄▄▄▄▄▄▄▄▄▄▄▄▄▄▄▄▄▄▄▄▄▄▄▄▄▄▄▄▄▄▄▄▄▄▄▄▄▄▄▄▄▄▄▄▄▄▄▄▄▄▄▄▄▄▄▄▄▄▄▄▄▄▄▄▄▄▄▄▄▄

                excali_layer {

                        bindings = <
&kp  LG(L)      &kp  LG(H)     &kp  N7       &kp  N8       &kp  N9        &kp  LG(G)                                                            &to  HDVB_L       &to  HDVB_L        &to  HDVB_L       &to  HDVB_L        &to  HDVB_L     &to  HDVB_L   
&trans        &hm_l wNAV_L N0 &hm LCTRL N1  &hm LALT N2   &hm LGUI N3    &kp  LG(RBKT)                                                          &to  HDVB_L       &to  HDVB_L        &to  HDVB_L       &to  HDVB_L        &to  HDVB_L     &to  HDVB_L   
&kp LG(V)        &kp  F    &kp  N4       &kp  N5       &kp  N6        &kp  LG(LBKT) &to  HDVB_L                             &trans               &to  HDVB_L       &to  HDVB_L        &to  HDVB_L       &to  HDVB_L        &to  HDVB_L     &to  HDVB_L   
                                                   &trans            &trans                &trans       &to  HDVB_L                             &trans              &trans        &trans             &trans 
                        >;
			
                        sensor-bindings = <&inc_dec_kp PG_UP PG_DN &inc_dec_kp C_VOL_UP C_VOL_DN>;
                };

// ▄▄▄▄▄▄▄▄▄▄▄▄▄▄▄▄▄▄▄▄▄▄▄▄▄▄▄▄▄▄▄▄▄▄▄▄▄▄▄▄▄▄▄▄▄▄▄▄▄▄▄▄▄▄▄▄▄▄▄▄▄▄▄▄▄▄▄▄▄▄▄▄▄▄▄▄▄▄▄▄▄▄▄▄▄▄▄▄▄▄▄▄▄▄▄▄▄▄▄▄▄▄▄▄▄▄▄▄▄▄▄▄▄▄▄▄▄▄▄▄▄▄▄▄▄▄▄▄▄▄▄▄▄▄▄▄▄▄▄▄▄▄

                capital_uml_layer {

                        bindings = <
&trans        &trans             &kp LS(LA(F20))   &trans            &trans                &trans                                                               &trans        &trans             &trans            &trans            &trans                &trans
&trans        &kp LS(LA(F16))    &trans            &trans            &trans                &trans                                                               &trans        &a_cap_uml         &trans            &trans            &trans                &trans
&trans        &trans             &trans            &trans            &trans                &kp LS(LA(F18))  &trans                          &trans              &trans        &u_cap_uml         &o_cap_uml        &trans            &trans                &trans
                                                   &trans            &trans                &trans       &trans                              &trans              &trans        &trans             &trans 
                        >;
			
                        sensor-bindings = <&inc_dec_kp PG_UP PG_DN &inc_dec_kp C_VOL_UP C_VOL_DN>;
                };

                scroll_layer {

                        bindings = <
&trans         &kp  CARET     &kp  N7       &kp  N8       &kp  N9        &kp  LT                                                                &trans        &kp  UP    &kp   D     &kp   U      &kp  DOWN          &trans
&trans        &hm_l NAV_L N0 &hm LCTRL N1  &hm LALT N2   &hm LGUI N3    &kp  GT                                                              &trans        &kp H         &kp J            &kp K            &kp L                &trans
&trans       &kp  PIPE     &kp  N4       &kp  N5       &kp  N6        &kp  DOLLAR   &trans                          &trans              &trans        &trans         &kp LS(G)        &gg             &trans                &trans
                                                   &trans            &trans                &trans       &trans                              &trans              &trans        &trans             &trans 
                        >;
			
                        sensor-bindings = <&inc_dec_kp PG_UP PG_DN &inc_dec_kp C_VOL_UP C_VOL_DN>;
                };

                adj_layer {
/* ADJUST
 * -------------------------------------------------------------------------------------------------------------------------------------
 * |       | QWERTY| DVORAK| COLEMK|       |       |-----------------------------------|       |  F11  |  F12  |Prt Scr|EP_OFF | EP_ON |
 * | RESET | BT 0  | BT 1  | BT 2  | BT 3  | BT 4  |-----------------------------------|       |       |Vol+   | Play  |       | RESET |
 * |       | LGUI  | LALT  | LCTRL | LSHIFT|       |BT CLR |-------------------|       |       |       |OUT_USB|OUT_BLE|       | BOOTL |
 *                                 |       |       |       |       |---|       |       |       |       |
 */
                        bindings = <
&none         &to  HDVB_L   &to wHDVB_L   &none         &kp C_PWR     &kp C_SLEEP                                                                       &none             &kp  C_BRI_DN      &kp  C_BRI_UP    &kp PRINTSCREEN   &ext_power EP_OFF  &ext_power EP_ON
&none         &bt  BT_SEL 0 &bt  BT_SEL 1 &bt  BT_SEL 2 &bt  BT_SEL 3 &bt  BT_SEL 4                                                                     &kp  C_MUTE       &kp  C_VOL_DN      &kp  C_VOL_UP    &kp  C_PP      &none           &kp  D
&none         &kp  LGUI     &kp  LALT     &kp  LCTRL    &kp LSHIFT    &none         &none                                              &bt BT_CLR       &none             &none              &out  OUT_USB    &out  OUT_BLE  &none           &bootloader
                                                        &trans        &trans        &trans        &trans                 &trans        &trans           &trans            &trans 
                        >;
			
                        sensor-bindings = <&inc_dec_kp C_VOL_UP C_VOL_DN &inc_dec_kp PG_UP PG_DN>;
                };
        };
};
